# RZT2H register map
Vendor: Renesas Electronics Corporation; Series: RZT; File version: 1.00.00
CPU: other r0p0, little endian, MPU, no FPU, VTOR, 4 interrupt priority bits, 624 interrupts
Registers are 32-bit, read-write, reset 0x0 unless marked. A register's access mark holds for its fields unless they carry their own. Offsets are from the block's base; [hi:lo] are bit positions; {n}, {i} and the like mark numbered series.

## ENDAT0 — EnDat2.2 Unit 0
Base 0x90204000
Same registers: ENDAT{n} {0x90204000+0x10000*n} (n=1..11), ENDAT12 0x90304000, ENDAT13 0x90314000, ENDAT14 0x90324000, ENDAT15 0x90334000
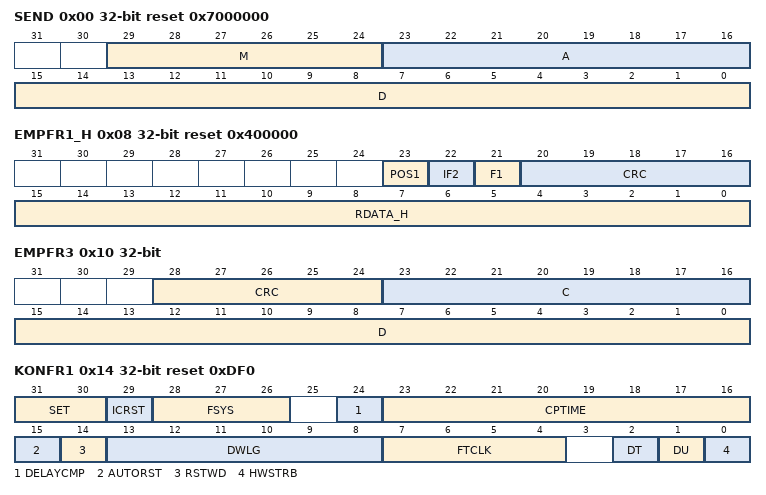
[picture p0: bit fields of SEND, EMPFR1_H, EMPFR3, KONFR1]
0x00 SEND reset 0x7000000
  [29:24] M — Mode command
  [23:16] A — Memory Range Select (MRS) code, Address, Port address
  [15:0] D — Parameters, Instructions
0x04 EMPFR1_L ro — Receive Register 1, Low Double Word
  [31:0] RDATA_L — Received data, bit 31 to bit 0
0x08 EMPFR1_H ro reset 0x400000 — Receive Register 1, High Double Word
  [23] POS1 — Absolute position value 1
    0=No Pos1; 1=Pos1
  [22] IF2 — Safety-relevant error bit F2 inversion
    0=Error occurred or if forced dynamic sampling is active; 1=No error occurred
  [21] F1 — Safety-relevant error bit F1
    0=No error occurred; 1=Error occurred or if forced dynamic sampling is active
  [20:16] CRC — Received CRC
  [15:0] RDATA_H — Received data, bit 47 to bit 32
0x0C EMPFR2 ro — Receive Register 2
  [31:0] RDATA2 — Received data 2
0x10 EMPFR3 ro — Receive Register 3
  [28:24] CRC — CRC for additional information 1
  [23:16] C — Memory Range Select (MRS) code in the additional information 1
  [15:0] D — Data in the additional information 1
0x14 KONFR1 reset 0xDF0 — Configuration Register 1
  [31:30] SET — EnDat set
    0=Not permitted; 1=Not permitted; 2=EnDat; 3=Not permitted
  [29] ICRST — IC reset
    0=IC reset inactive; 1=IC reset active
  [28:26] FSYS — System clock frequency (fsys)
    6=100 MHz; other=Others (Not permitted)
  [24] DELAYCMP — Delay compensation
    0=Delay compensation off; 1=Delay compensation on
  [23:16] CPTIME — Cable propagation time
  [15] AUTORST — Automatic reset
    0=Resetting of the above-mentioned registers must be performed by the application; 1=Resetting of the above-mentioned registers is done automatically. However, this resetting only occurs in the next EnDat transmission with the start of data reception.
  [14] RSTWD — Reset window
    0=Resetting of the registers mentioned above can be performed at any time. (i.e. without considering malfunctions).; 1=Resetting of the registers mentioned above must be performed within a defined time period for acceptance by the protocol engine
  [13:8] DWLG range 0x08..0x30 — Data word length
  [7:4] FTCLK
    {v}=16.67 MHz (v=0..3); 6=8.33 MHz; 11=4.16 MHz; 12=2 MHz; 13=1 MHz; 14=200 kHz; 15=100 kHz; other=Others (Not permitted)
  [2] DT
    0=Continuous clock off; 1=Continuous clock on
  [1] DU
    0=Data transfer according to flag set in the status register; 1=Data transfer despite the flag in the status register
  [0] HWSTRB — Hardware strobe
    0=HW strobe not enabled; 1=HW strobe enabled
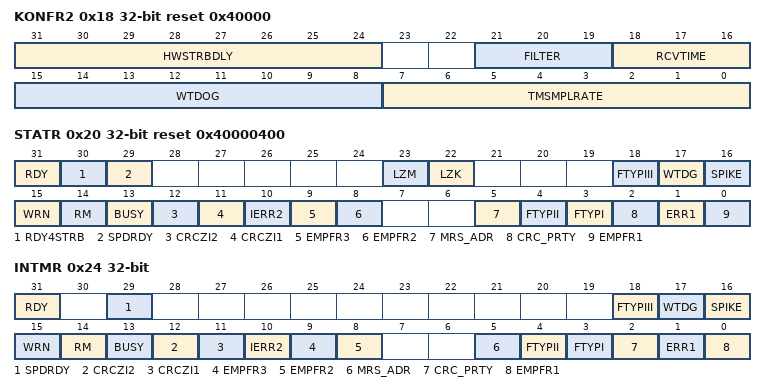
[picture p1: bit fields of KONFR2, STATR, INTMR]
0x18 KONFR2 reset 0x40000 — Configuration Register 2
  [31:24] HWSTRBDLY — Hardware strobe delay
  [21:19] FILTER
    0=Off; {v}={v+2} cycles (v=1..4); 5=10 cycles; 6=20 cycles; 7=40 cycles
  [18:16] RCVTIME — Recovery time III tST
    0=1/2 TCLK; 1=0.5 us; 2=1 us; 3=1.5 us; 4=2 us; 5=4 us; 6=8 us; 7=10 us
  [15:8] WTDOG — Watchdog
  [7:0] TMSMPLRATE — Timer for sampling rate
0x20 STATR reset 0x40000400 — Status Register
  [31] RDY — Ready
    0=No ready; 1=Ready
  [30] RDY4STRB — Ready for strobe
    0=No ready; 1=Ready
  [29] SPDRDY — Speed ready
    0=No new velocity value calculated; 1=New velocity value calculated
  [23] LZM — Propagation time measurement
    0=LZM incomplete; 1=LZM complete
  [22] LZK — Delay compensation
    0=LZK inactive; 1=LZK active
  [18] FTYPIII — F Type III
    0=The error did not occur; 1=The error occurred
  [17] WTDG — Watchdog
    0=Watchdog not triggered; 1=Watchdog triggered
  [16] SPIKE
    0=No spike; 1=Spike occurred
  [15] WRN
    0=WRN = 0; 1=WRN = 1
  [14] RM
    0=RM = 0; 1=RM = 1
  [13] BUSY
    0=Busy = 0; 1=Busy = 1
  [12] CRCZI2
    0=CRC check of ZI2 okay; 1=CRC check of ZI2 faulty
  [11] CRCZI1
    0=CRC check of ZI1 okay; 1=CRC check of ZI1 faulty
  [10] IERR2 — /Error2
    0=/Error2 occurred; 1=/Error2 did not occur
  [9] EMPFR3 — EMPFR3 register update
    0=EMPFR3 not updated; 1=EMPFR3 updated
  [8] EMPFR2 — EMPFR2 register update
    0=EMPFR2 not updated; 1=EMPFR2 updated
  [5] MRS_ADR
    0=No acknowledgment or addressing error has occurred; 1=An acknowledgment or addressing error has occurred
  [4] FTYPII — F Type II
    0=A Type II error did not occur; 1=A Type II error occurred
  [3] FTYPI — F Type I
    0=A type I error did not occur; 1=A type I error occurred
  [2] CRC_PRTY — CRC-PW / parity
    0=CRC check okay; 1=CRC check faulty
  [1] ERR1 — Error 1
    0=Error1 did not occur; 1=Error1 occurred
  [0] EMPFR1 — EMPFR1 register update
    0=EMPFR1 register not updated; 1=EMPFR1 register updated
0x24 INTMR — Interrupt Mask Register
  [all] fields
    0=Masked; 1=Not masked
  [31] RDY — Interrupt mask for Ready
  [29] SPDRDY — Interrupt mask for Speed ready
  [18] FTYPIII — Interrupt mask for F Type III
  [17] WTDG — Interrupt mask for Watchdog
  [16] SPIKE — Interrupt mask for Spike
  [15] WRN — Interrupt mask for WRN
  [14] RM — Interrupt mask for RM
  [13] BUSY — Interrupt mask for Busy
  [12] CRCZI2 — Interrupt mask for CRC-ZI2
  [11] CRCZI1 — Interrupt mask for CRC-ZI1
  [10] IERR2 — Interrupt mask for /Error2
  [9] EMPFR3 — Interrupt mask for EMPFR3 register update
  [8] EMPFR2 — Interrupt mask for EMPFR2 register update
  [5] MRS_ADR — Interrupt mask for MRS/Adr
  [4] FTYPII — Interrupt mask for F Type II
  [3] FTYPI — Interrupt mask for F Type I
  [2] CRC_PRTY — Interrupt mask for CRC-PW / parity
  [1] ERR1 — Interrupt mask for Error 1
  [0] EMPFR1 — Interrupt mask for EMPFR1 register update
0x38 SWSTRBR wo reset 0x40000400 — SW Strobe Register
0x3C IDR ro reset 0xE2260013 — ID Register
